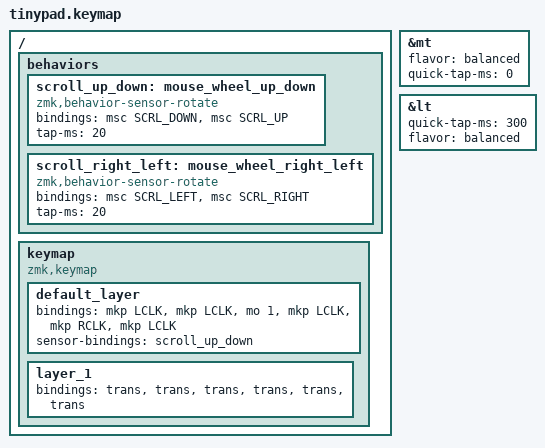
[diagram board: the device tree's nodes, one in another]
#include <input/processors.dtsi>
#include <dt-bindings/zmk/input_transform.h>
#include <zephyr/dt-bindings/input/input-event-codes.h>
#include <behaviors.dtsi>
#include <dt-bindings/zmk/bt.h>
#include <dt-bindings/zmk/pointing.h>
#include <dt-bindings/zmk/keys.h>
#include <dt-bindings/zmk/outputs.h>

#define ZMK_POINTING_SCRL_VAL 100
#define SCROLL 1

&mt {
    flavor = "balanced";
    quick-tap-ms = <0>;
};

&lt {
    quick-tap-ms = <300>;
    flavor = "balanced";
};

/ {
    behaviors {
        scroll_up_down: mouse_wheel_up_down {
            compatible = "zmk,behavior-sensor-rotate";
            #sensor-binding-cells = <0>;
            bindings = <&msc SCRL_DOWN>, <&msc SCRL_UP>;

            tap-ms = <20>;
        };

        scroll_right_left: mouse_wheel_right_left {
            compatible = "zmk,behavior-sensor-rotate";
            #sensor-binding-cells = <0>;
            bindings = <&msc SCRL_LEFT>, <&msc SCRL_RIGHT>;

            tap-ms = <20>;
        };
    };

    keymap {
        compatible = "zmk,keymap";

        default_layer {
            bindings = <
  &mkp LCLK  &mkp LCLK  &mo 1  &mkp LCLK  &mkp RCLK  &mkp LCLK
            >;

            sensor-bindings = <&scroll_up_down>;
        };

        layer_1 {
            bindings = <
&trans  &trans  &trans  &trans  &trans  &trans            >;
        };
    };

};
